VERSION ""

NS_ :

BS_:

BU_: HMI1 HMI2 VCU BMS MCU

BO_ 1984 HMI1Heartbeat: 2 HMI1
 SG_ HMI1Version : 0|16@1+ (1,0) [0|65535] ""  VCU

BO_ 1968 VCUHeartbeat: 2 VCU
 SG_ VCUVersion : 0|16@1+ (1,0) [0|65535] "" Vector__XXX

BO_ 2000 HMI2Heartbeat: 2 HMI2
 SG_ HMI2Version : 0|16@1+ (1,0) [0|65535] ""  VCU

BO_ 42 VCUSwitchControl: 5 VCU
 SG_ ABSState : 0|1@1+ (1,0) [0|1] ""  HMI1
 SG_ MirroringState : 1|1@1+ (1,0) [0|1] ""  HMI1
 SG_ LampState : 2|1@1+ (1,0) [0|1] ""  HMI1
 SG_ ErrorState : 3|1@1+ (1,0) [0|1] ""  HMI1
 SG_ OverheatState : 4|1@1+ (1,0) [0|1] ""  HMI1
 SG_ FingerState : 5|1@1+ (1,0) [0|1] ""  HMI1
 SG_ RemoteState : 6|1@1+ (1,0) [0|1] ""  HMI1
 SG_ DaylightState : 7|1@1+ (1,0) [0|1] ""  HMI1
 SG_ SeinLeftState : 8|1@1+ (1,0) [0|1] ""  HMI1
 SG_ SeinRightState : 9|1@1+ (1,0) [0|1] ""  HMI1
 SG_ HbarReverseState : 10|1@1+ (1,0) [0|1] ""  HMI1
 SG_ DriveMode : 16|2@1+ (1,0) [0|2] ""  HMI1
 SG_ TripMode : 18|2@1+ (1,0) [0|2] ""  HMI1
 SG_ ReportMode : 20|1@1+ (1,0) [0|1] ""  HMI1
 SG_ ModeState : 21|2@1+ (1,0) [0|2] ""  HMI1
 SG_ ModeHide : 23|1@1+ (1,0) [0|1] ""  HMI1
 SG_ SpeedVal : 24|8@1+ (1,0) [0|0] "km/h"  HMI1
 SG_ DiscurVal : 32|8@1+ (1,0) [0|0] "A"  HMI1

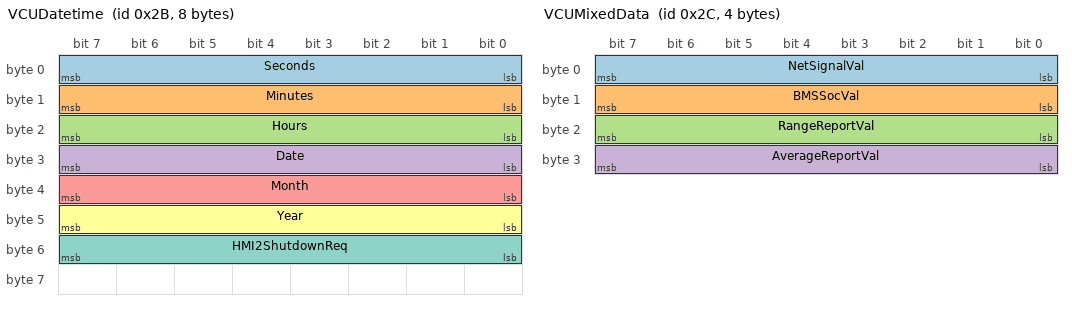
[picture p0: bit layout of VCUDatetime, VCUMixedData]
BO_ 43 VCUDatetime: 8 VCU
 SG_ Seconds : 0|8@1+ (1,0) [0|60] ""  HMI2
 SG_ Minutes : 8|8@1+ (1,0) [0|60] ""  HMI2
 SG_ Hours : 16|8@1+ (1,0) [0|24] ""  HMI2
 SG_ Date : 24|8@1+ (1,0) [0|31] ""  HMI2
 SG_ Month : 32|8@1+ (1,0) [0|12] ""  HMI2
 SG_ Year : 40|8@1+ (1,0) [0|0] ""  HMI2
 SG_ HMI2ShutdownReq : 48|8@1+ (1,0) [0|1] ""  HMI2

BO_ 44 VCUMixedData: 4 VCU
 SG_ NetSignalVal : 0|8@1+ (1,0) [0|100] "%"  HMI1
 SG_ BMSSocVal : 8|8@1+ (1,0) [0|100] "%"  HMI1
 SG_ RangeReportVal : 16|8@1+ (1,0) [0|0] "km"  HMI1
 SG_ AverageReportVal : 24|8@1+ (1,0) [0|0] "km/kwh"  HMI1

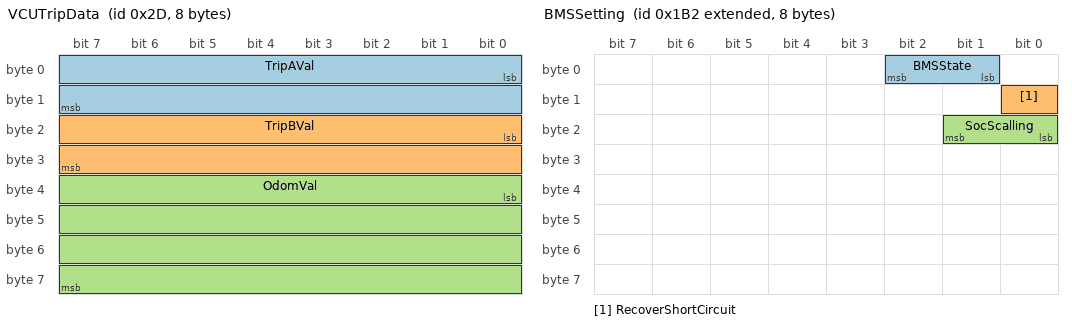
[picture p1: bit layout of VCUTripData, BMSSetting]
BO_ 45 VCUTripData: 8 VCU
 SG_ TripAVal : 0|16@1+ (1,0) [0|0] "m"  HMI1
 SG_ TripBVal : 16|16@1+ (1,0) [0|0] "m"  HMI1
 SG_ OdomVal : 32|32@1+ (1,0) [0|99999] "km"  HMI1

BO_ 2147484082 BMSSetting: 8 VCU
 SG_ BMSState : 1|2@1+ (1,0) [0|3] ""  BMS
 SG_ RecoverShortCircuit : 8|1@1+ (1,0) [0|1] ""  BMS
 SG_ SocScalling : 16|2@1+ (1,0) [0|3] ""  BMS

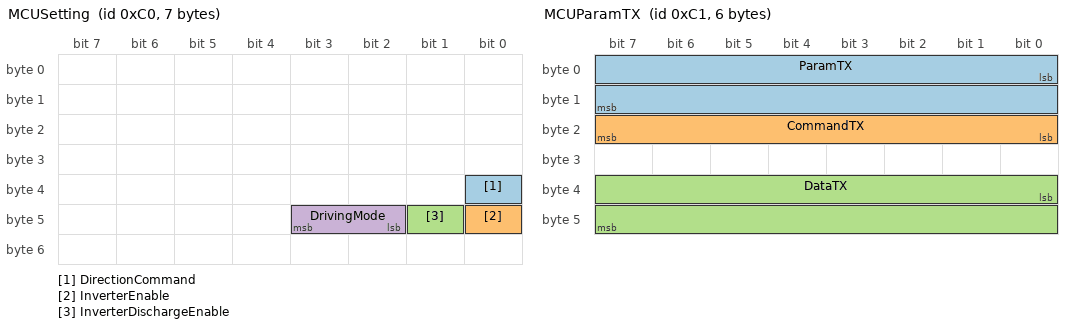
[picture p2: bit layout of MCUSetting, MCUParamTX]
BO_ 192 MCUSetting: 7 VCU
 SG_ DirectionCommand : 32|1@1+ (1,0) [0|0] ""  MCU
 SG_ InverterEnable : 40|1@1+ (1,0) [0|0] ""  MCU
 SG_ InverterDischargeEnable : 41|1@1+ (1,0) [0|0] ""  MCU
 SG_ DrivingMode : 42|2@1+ (1,0) [0|0] ""  MCU

BO_ 193 MCUParamTX: 6 VCU
 SG_ ParamTX : 0|16@1+ (1,0) [0|0] ""  MCU
 SG_ CommandTX : 16|8@1+ (1,0) [0|0] ""  MCU
 SG_ DataTX : 32|16@1+ (1,0) [0|0] ""  MCU

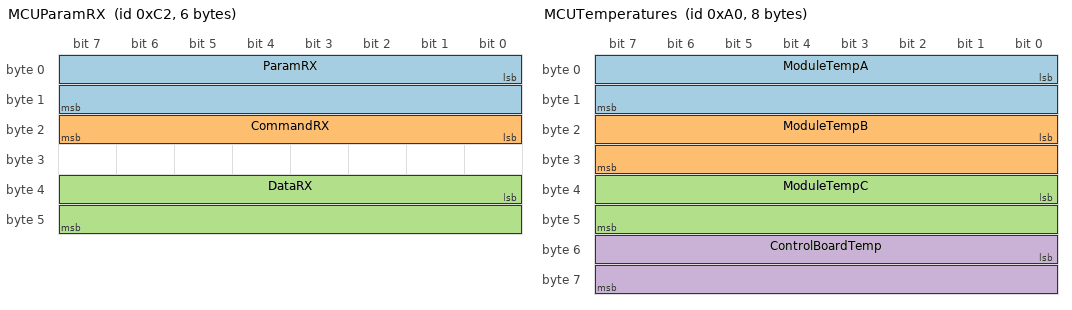
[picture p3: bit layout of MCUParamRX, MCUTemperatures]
BO_ 194 MCUParamRX: 6 MCU
 SG_ ParamRX : 0|16@1+ (1,0) [0|0] ""  VCU
 SG_ CommandRX : 16|8@1+ (1,0) [0|0] ""  VCU
 SG_ DataRX : 32|16@1+ (1,0) [0|0] ""  VCU

BO_ 160 MCUTemperatures: 8 MCU
 SG_ ModuleTempA : 0|16@1- (0.1,0) [0|0] "Celcius"  VCU
 SG_ ModuleTempB : 16|16@1- (0.1,0) [0|0] "Celcius"  VCU
 SG_ ModuleTempC : 32|16@1- (0.1,0) [0|0] "Celcius"  VCU
 SG_ ControlBoardTemp : 48|16@1- (0.1,0) [0|0] "Celcius"  VCU

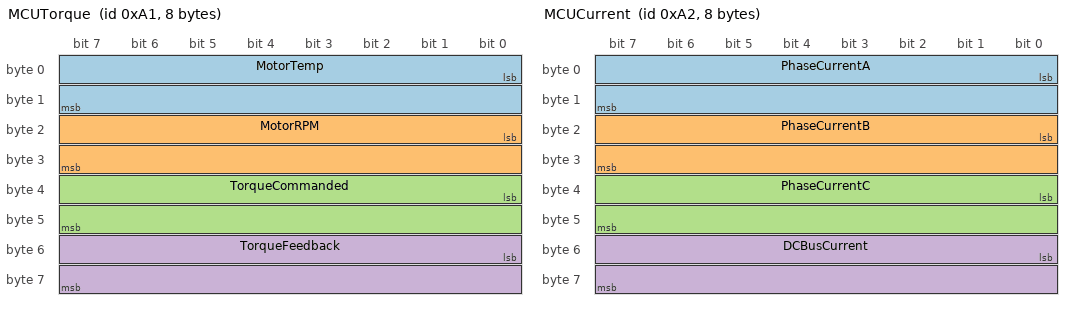
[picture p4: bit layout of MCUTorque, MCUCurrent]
BO_ 161 MCUTorque: 8 MCU
 SG_ MotorTemp : 0|16@1- (0.1,0) [0|0] "Celcius"  VCU
 SG_ MotorRPM : 16|16@1- (1,0) [0|0] "rpm"  VCU
 SG_ TorqueCommanded : 32|16@1- (0.1,0) [0|0] "Nm"  VCU
 SG_ TorqueFeedback : 48|16@1- (0.1,0) [0|0] "Nm"  VCU

BO_ 162 MCUCurrent: 8 MCU
 SG_ PhaseCurrentA : 0|16@1- (0.1,0) [0|0] "A"  VCU
 SG_ PhaseCurrentB : 16|16@1- (0.1,0) [0|0] "A"  VCU
 SG_ PhaseCurrentC : 32|16@1- (0.1,0) [0|0] "A"  VCU
 SG_ DCBusCurrent : 48|16@1- (0.1,0) [0|0] "A"  VCU

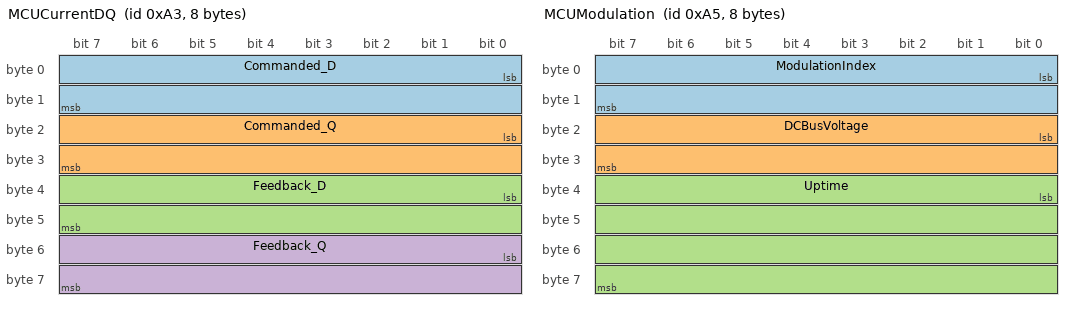
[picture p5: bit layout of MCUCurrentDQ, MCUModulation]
BO_ 163 MCUCurrentDQ: 8 MCU
 SG_ Commanded_D : 0|16@1- (0.1,0) [0|0] "A"  VCU
 SG_ Commanded_Q : 16|16@1- (0.1,0) [0|0] "A"  VCU
 SG_ Feedback_D : 32|16@1- (0.1,0) [0|0] "A"  VCU
 SG_ Feedback_Q : 48|16@1- (0.1,0) [0|0] "A"  VCU

BO_ 164 MCUFaultCodes: 8 MCU
 SG_ FaultPOST : 0|32@1+ (1,0) [0|0] ""  VCU
 SG_ FaultRUN : 32|32@1+ (1,0) [0|0] ""  VCU

BO_ 165 MCUModulation: 8 MCU
 SG_ ModulationIndex : 0|16@1- (0.001,0) [0|0] ""  VCU
 SG_ DCBusVoltage : 16|16@1- (0.1,0) [0|0] "Volt"  VCU
 SG_ Uptime : 32|32@1+ (0.003,0) [0|0] "Second"  VCU

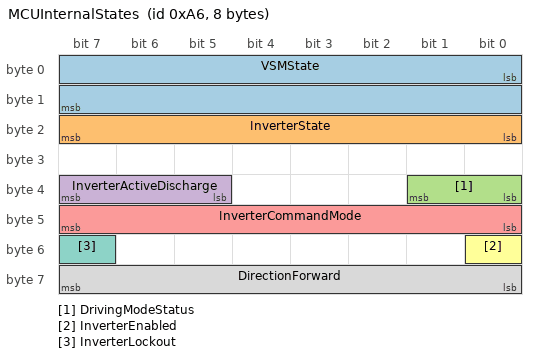
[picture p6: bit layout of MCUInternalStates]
BO_ 166 MCUInternalStates: 8 MCU
 SG_ VSMState : 0|16@1+ (1,0) [0|0] ""  VCU
 SG_ InverterState : 16|8@1+ (1,0) [0|0] ""  VCU
 SG_ DrivingModeStatus : 32|2@1+ (1,0) [0|0] ""  VCU
 SG_ InverterActiveDischarge : 37|3@1+ (1,0) [0|0] ""  VCU
 SG_ InverterCommandMode : 40|8@1+ (1,0) [0|0] ""  VCU
 SG_ InverterEnabled : 48|1@1+ (1,0) [0|0] ""  VCU
 SG_ InverterLockout : 55|1@1+ (1,0) [0|0] ""  VCU
 SG_ DirectionForward : 56|8@1+ (1,0) [0|0] ""  VCU

BO_ 26 DFUProgress: 8 VCU
 SG_ DeviceType : 0|32@1+ (1,0) [0|0] ""  HMI1
 SG_ Progress : 32|32@1- (1,0) [0|0] "%"  HMI1

BO_ 27 DFUCrc: 4 HMI1
 SG_ CrcOldVal : 0|32@1+ (1,0) [0|0] ""  VCU

BO_ 28 DFUPra: 4 VCU
 SG_ FirmwareSize : 0|32@1+ (1,0) [0|0] ""  HMI1

BO_ 29 DFUInit: 6 VCU
 SG_ FirmwareOffset : 0|32@1+ (1,0) [0|0] ""  HMI1
 SG_ BlockOffset : 32|16@1+ (1,0) [0|0] ""  HMI1

BO_ 30 DFURun: 8 VCU
 SG_ SubBlockOffset : 0|16@1+ (1,0) [0|0] ""  HMI1
 SG_ FirmwareData : 32|32@1+ (1,0) [0|0] ""  HMI1

BO_ 31 DFUPasca: 4 VCU
 SG_ CrcNewVal : 0|32@1+ (1,0) [0|0] ""  HMI1

BA_DEF_ BO_  "GenMsgBackgroundColor" STRING ;
BA_DEF_ BO_  "GenMsgForegroundColor" STRING ;
BA_DEF_DEF_  "GenMsgBackgroundColor" "#ffffff";
BA_DEF_DEF_  "GenMsgForegroundColor" "#000000";
VAL_ 42 DriveMode 0 "Economy" 1 "Standard" 2 "Sport" ;
VAL_ 42 TripMode 0 "TripA" 1 "TripB" 2 "Odometer" ;
VAL_ 42 ReportMode 0 "Range" 1 "Average" ;
VAL_ 42 ModeState 0 "Drive" 1 "Trip" 2 "Report" ;
VAL_ 2147484082 BMSState 0 "Idle" 1 "Discharge" 2 "Charge" 3 "Full" ;
VAL_ 2147484082 SocScalling 0 "15_85" 1 "20_80" 2 "10_90" 3 "0_100" ;
VAL_ 192 DirectionCommand 0 "CW" 1 "CCW" ;
VAL_ 192 DrivingMode 0 "Economic" 1 "Standard" 2 "Sport" ;
VAL_ 193 ParamTX 80 "EconomicDiscurMax" 81 "EconomicTorqueMax" 82 "EconomicRBSSwitch" 83 "StandardDiscurMax" 84 "StandardTorqueMax" 85 "StandardRBSSwitch" 86 "SportDiscurMax" 87 "SportTorqueMax" 88 "SportRBSSwitch" 128 "SpeedMax" ;
VAL_ 193 CommandTX 0 "Read" 1 "Write" ;
VAL_ 166 VSMState 0 "Start" 1 "Pre-charge Init" 2 "Pre-charge Active" 3 "Pre-charge Complete" 4 "Wait" 5 "Ready" 6 "Motor Running" 7 "Blink Fault Code" 14 "Shutdown in Process" 15 "Recycle Power" ;
VAL_ 166 InverterState 0 "Power on" 1 "Stop" 2 "Open Loop" 3 "Closed Loop" 4 "Wait" 8 "Idle Run" 9 "Idle Stop" ;
VAL_ 166 DrivingModeStatus 0 "Economic" 1 "Standard" 2 "Sport" ;
VAL_ 166 InverterActiveDischarge 0 "DischargeDisabled" 1 "DischargeEnabled" 2 "SpeedCheck" 3 "DischargeActive" 4 "DischargeCompleted" ;
VAL_ 166 InverterCommandMode 0 "ModeCAN" 1 "ModeVSM" ;
SIG_VALTYPE_ 160 ModuleTempA : 1;
SIG_VALTYPE_ 160 ModuleTempB : 1;
SIG_VALTYPE_ 160 ModuleTempC : 1;
SIG_VALTYPE_ 160 ControlBoardTemp : 1;
SIG_VALTYPE_ 161 MotorTemp : 1;
SIG_VALTYPE_ 161 MotorRPM : 1;
SIG_VALTYPE_ 161 TorqueCommanded : 1;
SIG_VALTYPE_ 161 TorqueFeedback : 1;
SIG_VALTYPE_ 162 PhaseCurrentA : 1;
SIG_VALTYPE_ 162 PhaseCurrentB : 1;
SIG_VALTYPE_ 162 PhaseCurrentC : 1;
SIG_VALTYPE_ 162 DCBusCurrent : 1;
SIG_VALTYPE_ 163 Commanded_D : 1;
SIG_VALTYPE_ 163 Commanded_Q : 1;
SIG_VALTYPE_ 163 Feedback_D : 1;
SIG_VALTYPE_ 163 Feedback_Q : 1;
SIG_VALTYPE_ 165 DCBusVoltage : 1;
SIG_VALTYPE_ 26 Progress : 1;
